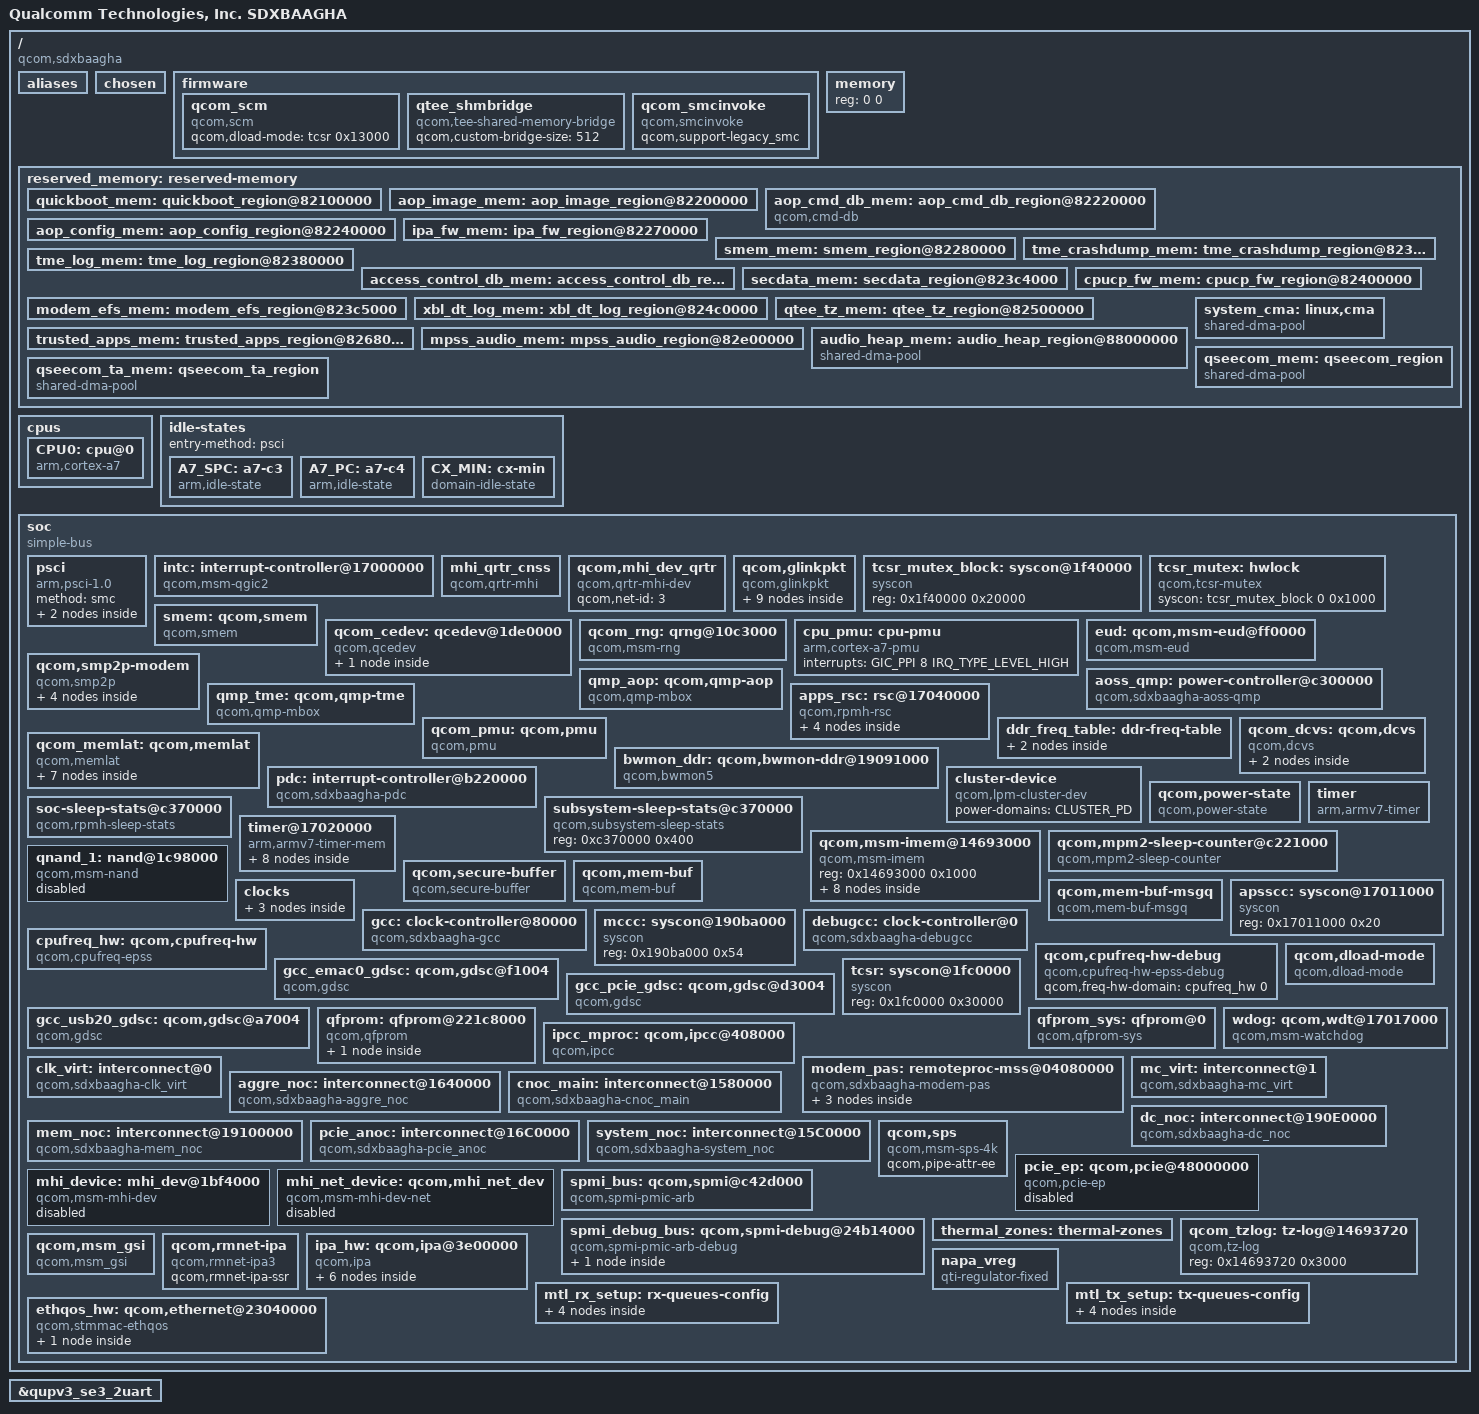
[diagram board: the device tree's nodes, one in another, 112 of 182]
#include <dt-bindings/interrupt-controller/arm-gic.h>
#include <dt-bindings/clock/qcom,rpmh.h>
#include <dt-bindings/clock/qcom,gcc-sdxbaagha.h>
#include <dt-bindings/soc/qcom,ipcc.h>
#include <dt-bindings/interconnect/qcom,icc.h>
#include <dt-bindings/soc/qcom,power-state.h>
#include <dt-bindings/interconnect/qcom,sdxbaagha.h>
#include <dt-bindings/regulator/qcom,rpmh-regulator-levels.h>
#include <dt-bindings/soc/qcom,rpmh-rsc.h>
#include <dt-bindings/gpio/gpio.h>
#include <dt-bindings/spmi/spmi.h>
#include <dt-bindings/soc/qcom,ipcc.h>

/ {
	#address-cells = <1>;
	#size-cells = <1>;

	model = "Qualcomm Technologies, Inc. SDXBAAGHA";
	compatible = "qcom,sdxbaagha";
	qcom,msm-id = <570 0x10000>, <571 0x10000>;
	interrupt-parent = <&intc>;

	aliases {
		serial0 = &qupv3_se3_2uart;
		serial1 = &qupv3_se0_2uart; /* MDM SAP UART Instance */
		hsuart0 = &qupv3_se1_4uart; /* HST BT HCI UART Instance */
	};

	chosen: chosen { };

	firmware: firmware { };

	memory { device_type = "memory"; reg = <0 0>; };

	reserved_memory: reserved-memory {
		#address-cells = <1>;
		#size-cells = <1>;
		ranges;

		quickboot_mem: quickboot_region@82100000 {
			no-map;
			reg = <0x82100000 0x100000>;
		};

		aop_image_mem: aop_image_region@82200000 {
			no-map;
			reg = <0x82200000 0x20000>;
		};

		aop_cmd_db_mem: aop_cmd_db_region@82220000 {
			compatible = "qcom,cmd-db";
			no-map;
			reg = <0x82220000 0x20000>;
		};

		aop_config_mem: aop_config_region@82240000 {
			no-map;
			reg = <0x82240000 0x20000>;
		};

		ipa_fw_mem: ipa_fw_region@82270000 {
			no-map;
			reg = <0x82270000 0x10000>;
		};

		smem_mem: smem_region@82280000 {
			no-map;
			reg = <0x82280000 0xc0000>;
		};

		tme_crashdump_mem: tme_crashdump_region@82340000 {
			no-map;
			reg = <0x82340000 0x40000>;
		};

		tme_log_mem: tme_log_region@82380000 {
			no-map;
			reg = <0x82380000 0x4000>;
		};

		access_control_db_mem: access_control_db_region@82384000 {
			no-map;
			reg = <0x82384000 0x40000>;
		};

		secdata_mem: secdata_region@823c4000 {
			no-map;
			reg = <0x823c4000 0x1000>;
		};

		modem_efs_mem: modem_efs_region@823c5000 {
			no-map;
			reg = <0x823c5000 0x10000>;
		};

		cpucp_fw_mem: cpucp_fw_region@82400000 {
			no-map;
			reg = <0x82400000 0x80000>;
		};

		xbl_dt_log_mem: xbl_dt_log_region@824c0000 {
			no-map;
			reg = <0x824c0000 0x20000>;
		};

		qtee_tz_mem: qtee_tz_region@82500000 {
			no-map;
			reg = <0x82500000 0x180000>;
		};

		trusted_apps_mem: trusted_apps_region@82680000 {
			no-map;
			reg = <0x82680000 0x600000>;
		};

		mpss_audio_mem: mpss_audio_region@82e00000 {
			no-map;
			reg = <0x82e00000 0x5000000>;
		};

		audio_heap_mem: audio_heap_region@88000000 {
			compatible = "shared-dma-pool";
			no-map;
			reg = <0x88000000 0x400000>;
		};

		/* global autoconfigured region for contiguous allocations */
		system_cma: linux,cma {
			compatible = "shared-dma-pool";
			alloc-ranges = <0x00000000 0xffffffff>;
			reusable;
			alignment = <0x400000>;
			size = <0x1800000>;
			linux,cma-default;
		};

		qseecom_mem: qseecom_region {
			compatible = "shared-dma-pool";
			alloc-ranges = <0x00000000 0xffffffff>;
			reusable;
			alignment = <0x400000>;
			size = <0x400000>;
		};

		qseecom_ta_mem: qseecom_ta_region {
			compatible = "shared-dma-pool";
			alloc-ranges = <0x00000000 0xffffffff>;
			reusable;
			alignment = <0x400000>;
			size = <0x400000>;
		};
	};

	cpus {
		#size-cells = <0>;
		#address-cells = <1>;

		CPU0: cpu@0 {
			device_type = "cpu";
			compatible = "arm,cortex-a7";
			reg = <0x0>;
			qcom,freq-domain = <&cpufreq_hw 0>;
			enable-method = "psci";
			cpu-idle-states = <&A7_SPC &A7_PC>;
			power-domains = <&CPU_PD0>;
			power-domain-names = "psci";
			#cooling-cells = <2>;
		};
	};

	idle-states {
		entry-method = "psci";

		A7_SPC: a7-c3 { /* C3 */
			compatible = "arm,idle-state";
			idle-state-name = "standalone-pc";
			entry-latency-us = <350>;
			exit-latency-us = <450>;
			min-residency-us = <1774>;
			arm,psci-suspend-param = <0x40000003>;
			local-timer-stop;
		};

		A7_PC: a7-c4 { /* C4 */
			compatible = "arm,idle-state";
			idle-state-name = "pc";
			entry-latency-us = <550>;
			exit-latency-us = <750>;
			min-residency-us = <6700>;
			arm,psci-suspend-param = <0x40000004>;
			local-timer-stop;
		};

		CX_MIN: cx-min { /* C8 */
			compatible = "domain-idle-state";
			idle-state-name = "cx-min";
			entry-latency-us = <750>;
			exit-latency-us = <2350>;
			min-residency-us = <9144>;
			arm,psci-suspend-param = <0x40000008>;
		};

	};

	soc: soc { };
};

&chosen {
	bootargs = "pcie_ports=compat cpufreq.default_governor=performance";
};

&soc {
	#address-cells = <1>;
	#size-cells = <1>;
	ranges;
	compatible = "simple-bus";

	psci {
		compatible = "arm,psci-1.0";
		 method = "smc";

		CPU_PD0: cpu-pd0 {
			#power-domain-cells = <0>;
			power-domains = <&CLUSTER_PD>;
		};

		CLUSTER_PD: cluster-pd {
			#power-domain-cells = <0>;
			domain-idle-states = <&CX_MIN>;
		};
	};

	intc: interrupt-controller@17000000 {
		compatible = "qcom,msm-qgic2";
		interrupt-controller;
		#interrupt-cells = <3>;
		reg = <0x17000000 0x1000>,
		      <0x17002000 0x1000>;
	};

	mhi_qrtr_cnss {
		compatible = "qcom,qrtr-mhi";
		qcom,dev-id = <0x1103>;
		qcom,net-id = <0>;
		qcom,low-latency;
	};

	qcom,mhi_dev_qrtr {
		compatible = "qcom,qrtr-mhi-dev";
		qcom,net-id = <3>;
	};

	qcom,glinkpkt {
		compatible = "qcom,glinkpkt";

		qcom,glinkpkt-at-mdm0 {
			qcom,glinkpkt-edge = "mpss";
			qcom,glinkpkt-ch-name = "DS";
			qcom,glinkpkt-dev-name = "at_mdm0";
		};

		qcom,glinkpkt-data5-cntl {
			qcom,glinkpkt-edge = "mpss";
			qcom,glinkpkt-ch-name = "DATA5_CNTL";
			qcom,glinkpkt-dev-name = "smdcntl0";
		};

		qcom,glinkpkt-data6-cntl {
			qcom,glinkpkt-edge = "mpss";
			qcom,glinkpkt-ch-name = "DATA6_CNTL";
			qcom,glinkpkt-dev-name = "smdcntl1";
		};

		qcom,glinkpkt-data40-cntl {
			qcom,glinkpkt-edge = "mpss";
			qcom,glinkpkt-ch-name = "DATA40_CNTL";
			qcom,glinkpkt-dev-name = "smdcntl8";
		};

		qcom,glinkpkt-data1 {
			qcom,glinkpkt-edge = "mpss";
			qcom,glinkpkt-ch-name = "DATA1";
			qcom,glinkpkt-dev-name = "smd7";
		};

		qcom,glinkpkt-data4 {
			qcom,glinkpkt-edge = "mpss";
			qcom,glinkpkt-ch-name = "DATA4";
			qcom,glinkpkt-dev-name = "smd8";
		};

		qcom,glinkpkt-data11 {
			qcom,glinkpkt-edge = "mpss";
			qcom,glinkpkt-ch-name = "DATA11";
			qcom,glinkpkt-dev-name = "smd11";
		};

		qcom,glinkpkt-data21 {
			qcom,glinkpkt-edge = "mpss";
			qcom,glinkpkt-ch-name = "DATA21";
			qcom,glinkpkt-dev-name = "smd21";
		};

		qcom,glinkpkt-data22 {
			qcom,glinkpkt-edge = "mpss";
			qcom,glinkpkt-ch-name = "DATA22";
			qcom,glinkpkt-dev-name = "smd22";
		};
	};

	tcsr_mutex_block: syscon@1f40000 {
		compatible = "syscon";
		reg = <0x1f40000 0x20000>;
	};

	tcsr_mutex: hwlock {
		compatible = "qcom,tcsr-mutex";
		syscon = <&tcsr_mutex_block 0 0x1000>;
		#hwlock-cells = <1>;
	};

	smem: qcom,smem {
		compatible = "qcom,smem";
		memory-region = <&smem_mem>;
		hwlocks = <&tcsr_mutex 3>;
	};

	qcom_cedev: qcedev@1de0000 {
		compatible = "qcom,qcedev";
		reg = <0x1de0000 0x20000>,
			<0x1dc4000 0x20000>;
		reg-names = "crypto-base","crypto-bam-base";
		interrupts = <GIC_SPI 252 IRQ_TYPE_LEVEL_HIGH>;
		qcom,bam-pipe-pair = <3>;
		qcom,ce-hw-instance = <0>;
		qcom,ce-device = <0>;
		qcom,ce-hw-shared;
		qcom,bam-ee = <0>;
		qcom,smmu-s1-enable;
		qcom,no-clock-support;
		interconnect-names = "data_path";
		interconnects = <&aggre_noc MASTER_CRYPTO &mc_virt SLAVE_EBI1>;
		iommus = <&apps_smmu 0x00A0 0x0>,
			<&apps_smmu 0x00A1 0x0>;
		qcom,iommu-dma = "atomic";

		qcom_cedev_ns_cb {
			compatible = "qcom,qcedev,context-bank";
			label = "ns_context";
			iommus = <&apps_smmu 0x00A1 0x0>;
		};
	};

	qcom_rng: qrng@10c3000 {
		compatible = "qcom,msm-rng";
		reg = <0x10c3000 0x1000>;
		qcom,no-qrng-config;
		qcom,no-clock-support;
	};

	cpu_pmu: cpu-pmu {
		compatible = "arm,cortex-a7-pmu";
		interrupts = <GIC_PPI 8 IRQ_TYPE_LEVEL_HIGH>;
	};

	eud: qcom,msm-eud@ff0000 {
		compatible = "qcom,msm-eud";
		interrupt-names = "eud_irq";
		interrupt-parent = <&pdc>;
		interrupts = <6 IRQ_TYPE_LEVEL_HIGH>;
		reg = <0xff0000 0x2000>,
			<0xff2000 0x1000>;
		reg-names = "eud_base", "eud_mode_mgr2";
		qcom,secure-eud-en;
		status = "ok";
	};

	qcom,smp2p-modem {
		compatible = "qcom,smp2p";
		qcom,smem = <435>, <428>;
		interrupt-parent = <&ipcc_mproc>;
		interrupts = <IPCC_CLIENT_MPSS IPCC_MPROC_SIGNAL_SMP2P
				IRQ_TYPE_EDGE_RISING>;
		mboxes = <&ipcc_mproc IPCC_CLIENT_MPSS IPCC_MPROC_SIGNAL_SMP2P>;
		qcom,local-pid = <0>;
		qcom,remote-pid = <1>;

		modem_smp2p_out: master-kernel {
			qcom,entry-name = "master-kernel";
			#qcom,smem-state-cells = <1>;
		};

		modem_smp2p_in: slave-kernel {
			qcom,entry-name = "slave-kernel";
			interrupt-controller;
			#interrupt-cells = <2>;
		};

		smp2p_ipa_1_out: qcom,smp2p-ipa-1-out {
			qcom,entry-name = "ipa";
			#qcom,smem-state-cells = <1>;
		};

		 /* ipa - inbound entry from mss */
		smp2p_ipa_1_in: qcom,smp2p-ipa-1-in {
			qcom,entry-name = "ipa";
			interrupt-controller;
			#interrupt-cells = <2>;
		};
	};

	aoss_qmp: power-controller@c300000 {
		compatible = "qcom,sdxbaagha-aoss-qmp";
		reg = <0xc310000 0x1000>;
		interrupt-parent = <&ipcc_mproc>;
		interrupts = <IPCC_CLIENT_AOP
				IPCC_MPROC_SIGNAL_GLINK_QMP
				IRQ_TYPE_EDGE_RISING>;
		mboxes = <&ipcc_mproc IPCC_CLIENT_AOP
				IPCC_MPROC_SIGNAL_GLINK_QMP>;

		#power-domain-cells = <1>;
		#clock-cells = <0>;
	};

	qmp_aop: qcom,qmp-aop {
		compatible = "qcom,qmp-mbox";
		qcom,qmp = <&aoss_qmp>;
		label = "aop";
		#mbox-cells = <1>;
	};

	qmp_tme: qcom,qmp-tme {
		compatible = "qcom,qmp-mbox";
		qcom,remote-pid = <14>;
		mboxes = <&ipcc_mproc IPCC_CLIENT_TME
			  IPCC_MPROC_SIGNAL_GLINK_QMP>;
		mbox-names = "tme_qmp";
		interrupt-parent = <&ipcc_mproc>;
		interrupts = <IPCC_CLIENT_TME
			      IPCC_MPROC_SIGNAL_GLINK_QMP
			      IRQ_TYPE_EDGE_RISING>;

		label = "tme";
		qcom,early-boot;
		priority = <0>;
		mbox-desc-offset = <0x0>;
		#mbox-cells = <1>;
	};

	apps_rsc: rsc@17040000 {
		label = "apps_rsc";
		compatible = "qcom,rpmh-rsc";
		reg = <0x17040000 0x10000>,
		      <0x17050000 0x10000>,
		      <0x17060000 0x10000>;
		reg-names = "drv-0", "drv-1", "drv-2";
		qcom,drv-count = <3>;
		interrupts = <GIC_SPI 16 IRQ_TYPE_LEVEL_HIGH>,
			     <GIC_SPI 17 IRQ_TYPE_LEVEL_HIGH>, /* dummy */
			     <GIC_SPI 17 IRQ_TYPE_LEVEL_HIGH>;
		power-domains = <&CLUSTER_PD>;

		apps_rsc_drv2: drv@2 {
			qcom,drv-id = <2>;
			qcom,tcs-offset = <0xd00>;
			channel@0 {
				qcom,tcs-config = <ACTIVE_TCS    2>,
						  <SLEEP_TCS     3>,
						  <WAKE_TCS      3>,
						  <CONTROL_TCS   0>,
						  <FAST_PATH_TCS 0>;
			};

			apps_bcm_voter: bcm_voter {
				compatible = "qcom,bcm-voter";
			};

			rpmhcc: clock-controller {
				compatible = "qcom,sdxbaagha-rpmh-clk";
				#clock-cells = <1>;
			};
		};
	};

	qcom_pmu: qcom,pmu {
		compatible = "qcom,pmu";
		qcom,pmu-events-tbl =
			< 0x0008 0x01 0xFF 0xFF >,
			< 0x0011 0x01 0xFF 0xFF >,
			< 0x0017 0x01 0xFF 0xFF >;
	};

	ddr_freq_table: ddr-freq-table {
		ddr2 {
			qcom,ddr-type = <2>;
			qcom,freq-tbl =
				<  211200 >,
				<  451200 >,
				<  499200 >,
				<  531500 >;
		};

		ddr4 {
			qcom,ddr-type = <7>;
			qcom,freq-tbl =
				<  211200 >,
				<  451200 >,
				<  556800 >,
				<  681600 >,
				<  768000 >;
		};
	};

	qcom_dcvs: qcom,dcvs {
		compatible = "qcom,dcvs";
		#address-cells = <1>;
		#size-cells = <1>;
		ranges;

		qcom_ddr_dcvs_hw: ddr {
			compatible = "qcom,dcvs-hw";
			qcom,dcvs-hw-type = <0>;
			qcom,bus-width = <4>;
			qcom,freq-tbl = <&ddr_freq_table>;

			ddr_dcvs_sp: sp {
				compatible = "qcom,dcvs-path";
				qcom,dcvs-path-type = <0>;
				interconnects = <&mc_virt MASTER_LLCC
						&mc_virt SLAVE_EBI1>;
			};
		};
	};

	qcom_memlat: qcom,memlat {
		compatible = "qcom,memlat";
		ddr {
			compatible = "qcom,memlat-grp";
			qcom,target-dev = <&qcom_ddr_dcvs_hw>;
			qcom,sampling-path = <&ddr_dcvs_sp>;
			qcom,miss-ev = <0x17>;

			silver {
				compatible = "qcom,memlat-mon";
				qcom,cpulist = <&CPU0>;
				qcom,sampling-enabled;
				ddr2-tbl {
					qcom,ddr-type = <2>;
					qcom,cpufreq-memfreq-tbl =
						<  288000  211200 >,
						<  672000  451200 >,
						< 1248000  499200 >,
						< 1708800  531500 >;
				};

				ddr4-tbl {
					qcom,ddr-type = <7>;
					qcom,cpufreq-memfreq-tbl =
						<  288000  211200 >,
						<  364800  451200 >,
						<  672000  556800 >,
						< 1248000  681600 >,
						< 1708800  768000 >;
				};
			};

			silver-compute {
				compatible = "qcom,memlat-mon";
				qcom,cpulist = <&CPU0>;
				qcom,sampling-enabled;
				qcom,compute-mon;
				ddr2-tbl {
					qcom,ddr-type = <2>;
					qcom,cpufreq-memfreq-tbl =
						< 1248000  211200 >,
						< 1708800  531500 >;
				};

				ddr4-tbl {
					qcom,ddr-type = <7>;
					qcom,cpufreq-memfreq-tbl =
						< 1248000  211200 >,
						< 1708800  768000 >;
				};
			};
		};
	};

	bwmon_ddr: qcom,bwmon-ddr@19091000 {
		compatible = "qcom,bwmon5";
		reg = <0x19091000 0x1000>;
		reg-names = "base";
		interrupts = <GIC_SPI 257 IRQ_TYPE_LEVEL_HIGH>;
		qcom,hw-timer-hz = <19200000>;
		qcom,count-unit = <0x10000>;
		qcom,target-dev = <&qcom_ddr_dcvs_hw>;
	};

	pdc: interrupt-controller@b220000 {
		compatible = "qcom,sdxbaagha-pdc", "qcom,pdc";
		reg = <0xb220000 0x10000>;
		qcom,pdc-ranges = <1 148 6>, <9 156 2>, <17 164 7>,
				  <26 173 1>, <29 176 1>, <40 187 1>,
				  <46 193 6>, <52 266 32>, <84 249 1>,
				  <85 256 1>, <86 315 4>, <90 43 1>,
				  <91 45 1>, <92 154 2>, <94 158 6>,
				  <100 171 2>, <102 174 1>, <103 23 7>,
				  <110 147 1>, <111 31 4>, <115 175 1>,
				  <116 177 10>, <126 188 5>;
		#interrupt-cells = <2>;
		interrupt-parent = <&intc>;
		interrupt-controller;
	};

	cluster-device {
		compatible = "qcom,lpm-cluster-dev";
		power-domains = <&CLUSTER_PD>;
	};

	qcom,power-state {
		compatible = "qcom,power-state";
		qcom,subsys-name = "mpss";
		qcom,rproc-handle = <&modem_pas>;
		qcom,rproc-state = <RPROC_SUSPEND>;
	};

	soc-sleep-stats@c370000 {
		compatible = "qcom,rpmh-sleep-stats";
		reg = <0xc370000 0x400>;
		ss-name = "modem", "apss";
	};

	subsystem-sleep-stats@c370000 {
		compatible = "qcom,subsystem-sleep-stats";
		reg = <0xc370000 0x400>;
	};

	timer {
		compatible = "arm,armv7-timer";
		interrupts = <1 13 0xf08>,
			<1 12 0xf08>,
			<1 10 0xf08>,
			<1 11 0xf08>;
		clock-frequency = <19200000>;
	};

	timer@17020000 {
		#address-cells = <1>;
		#size-cells = <1>;
		ranges;
		compatible = "arm,armv7-timer-mem";
		reg = <0x17020000 0x1000>;
		clock-frequency = <19200000>;

		frame@17021000 {
			frame-number = <0>;
			interrupts = <0 7 0x4>,
				     <0 6 0x4>;
			reg = <0x17021000 0x1000>,
			      <0x17022000 0x1000>;
		};

		frame@17023000 {
			frame-number = <1>;
			interrupts = <0 8 0x4>;
			reg = <0x17023000 0x1000>;
			status = "disabled";
		};

		frame@17024000 {
			frame-number = <2>;
			interrupts = <0 9 0x4>;
			reg = <0x17024000 0x1000>;
			status = "disabled";
		};

		frame@17025000 {
			frame-number = <3>;
			interrupts = <0 10 0x4>;
			reg = <0x17025000 0x1000>;
			status = "disabled";
		};

		frame@17026000 {
			frame-number = <4>;
			interrupts = <0 11 0x4>;
			reg = <0x17026000 0x1000>;
			status = "disabled";
		};

		frame@17027000 {
			frame-number = <5>;
			interrupts = <0 12 0x4>;
			reg = <0x17027000 0x1000>;
			status = "disabled";
		};

		frame@17028000 {
			frame-number = <6>;
			interrupts = <0 13 0x4>;
			reg = <0x17028000 0x1000>;
			status = "disabled";
		};

		frame@17029000 {
			frame-number = <7>;
			interrupts = <0 14 0x4>;
			reg = <0x17029000 0x1000>;
			status = "disabled";
		};
	};

	qcom,msm-imem@14693000 {
		compatible = "qcom,msm-imem";
		reg = <0x14693000 0x1000>;
		ranges = <0x0 0x14693000 0x1000>;
		#address-cells = <1>;
		#size-cells = <1>;

		mem_dump_table@10  {
			compatible = "qcom,msm-imem-mem_dump_table";
			reg = <0x10 0x8>;
		};

		restart_reason@65c {
			compatible = "qcom,msm-imem-restart_reason";
			reg = <0x65c 0x4>;
		};

		dload_type@1c {
			compatible = "qcom,msm-imem-dload-type";
			reg = <0x1c 0x4>;
		};

		boot_stats@6b0 {
			compatible = "qcom,msm-imem-boot_stats";
			reg = <0x6b0 0x20>;
		};

		kaslr_offset@6d0 {
			compatible = "qcom,msm-imem-kaslr_offset";
			reg = <0x6d0 0xc>;
		};

		pil@94c {
			compatible = "qcom,pil-reloc-info";
			reg = <0x94c 0xc8>;
		};

		pil@6dc {
			compatible = "qcom,msm-imem-pil-disable-timeout";
			reg = <0x6dc 0x4>;
		};

		diag_dload@c8 {
			compatible = "qcom,msm-imem-diag-dload";
			reg = <0xc8 0xc8>;
		};
	};

	qcom,mpm2-sleep-counter@c221000 {
		compatible = "qcom,mpm2-sleep-counter";
		reg = <0xc221000 0x1000>;
		clock-frequency = <32768>;
	};

	qnand_1: nand@1c98000 {
		compatible = "qcom,msm-nand";
		reg =   <0x01c98000 0x1000>,
			<0x01c9c000 0x1c000>;
		reg-names =     "nand_phys",
				"bam_phys";
		qcom,reg-adjustment-offset = <0x4000>;

		interrupts = <GIC_SPI 135 IRQ_TYPE_LEVEL_HIGH>;
		interrupt-names = "bam_irq";

		clock-names = "core_clk";
		clocks = <&rpmhcc RPMH_QPIC_CLK>;

		interconnects = <&aggre_noc MASTER_QPIC &mc_virt SLAVE_EBI1>;
		interconnect-names = "nand-ddr";
		qcom,msm-bus,name = "qpic_nand";
		qcom,msm-bus,num-cases = <2>;
		qcom,msm-bus,num-paths = <1>;
		qcom,msm-bus,vectors-KBps =
			<0 0>,
		/* Voting for max b/w on PNOC bus for now */
			<1057800 725760>;

		iommus = <&apps_smmu 0x160 0x3>;
		qcom,iommu-dma = "atomic";

		status = "disabled";
	};

	qcom,secure-buffer {
		compatible = "qcom,secure-buffer";
	};

	qcom,mem-buf {
		compatible = "qcom,mem-buf";
		qcom,mem-buf-capabilities = "supplier";
		qcom,vmid = <3>;
	};

	qcom,mem-buf-msgq {
		compatible = "qcom,mem-buf-msgq";
	};

	clocks {
		xo_board: xo_board {
			compatible = "fixed-clock";
			clock-frequency = <38400000>;
			clock-output-names = "xo_board";
			#clock-cells = <0>;
		};

		sleep_clk: sleep_clk {
			compatible = "fixed-clock";
			clock-frequency = <32000>;
			clock-output-names = "sleep_clk";
			#clock-cells = <0>;
		};

		pcie_pipe_clk: pcie_pipe_clk {
			compatible = "fixed-clock";
			clock-frequency = <1000>;
			clock-output-names = "pcie_pipe_clk";
			#clock-cells = <0>;
		};
	};

	gcc: clock-controller@80000 {
		compatible = "qcom,sdxbaagha-gcc", "syscon";
		reg = <0x80000 0x1f4200>;
		reg-name = "cc_base";
		vdd_cx-supply = <&VDD_CX_LEVEL>;
		vdd_mxa-supply = <&VDD_MXA_LEVEL>;
		vdd_mxc-supply = <&VDD_MXC_LEVEL>;
		clocks = <&rpmhcc RPMH_CXO_CLK>,
			 <&pcie_pipe_clk>,
			 <&sleep_clk>;
		clock-names = "bi_tcxo",
			      "pcie_pipe_clk",
			      "sleep_clk";
		#clock-cells = <1>;
		#reset-cells = <1>;
	};

	apsscc: syscon@17011000 {
		compatible = "syscon";
		reg = <0x17011000 0x20>;
	};

	mccc: syscon@190ba000 {
		compatible = "syscon";
		reg = <0x190ba000 0x54>;
	};

	debugcc: clock-controller@0 {
		compatible = "qcom,sdxbaagha-debugcc";
		qcom,gcc = <&gcc>;
		qcom,mccc = <&mccc>;
		qcom,apsscc = <&apsscc>;
		clocks = <&rpmhcc RPMH_CXO_CLK>,
			 <&gcc 0>;
		clock-names = "xo_clk_src",
			      "gcc";
		#clock-cells = <1>;
	};

	cpufreq_hw: qcom,cpufreq-hw {
		compatible = "qcom,cpufreq-epss";
		reg = <0x17191000 0x1000>;
		reg-names = "freq-domain0";
		clocks = <&rpmhcc RPMH_CXO_CLK>, <&gcc GPLL0>;
		clock-names = "xo", "alternate";
		interrupts = <GIC_SPI 30 IRQ_TYPE_LEVEL_HIGH>;
		interrupt-names = "dcvsh0_int";
		#freq-domain-cells = <1>;
	};

	qcom,cpufreq-hw-debug {
		compatible = "qcom,cpufreq-hw-epss-debug";
		qcom,freq-hw-domain = <&cpufreq_hw 0>;
	};

	/* GCC GDSCs */
	gcc_emac0_gdsc: qcom,gdsc@f1004 {
		compatible = "qcom,gdsc";
		reg = <0xf1004 0x4>;
		regulator-name = "gcc_emac0_gdsc";
		parent-supply = <&VDD_MXC_LEVEL>;
		qcom,retain-regs;
		qcom,support-hw-trigger;
	};

	gcc_pcie_gdsc: qcom,gdsc@d3004 {
		compatible = "qcom,gdsc";
		reg = <0xd3004 0x4>;
		regulator-name = "gcc_pcie_gdsc";
		parent-supply = <&VDD_CX_LEVEL>;
		qcom,retain-regs;
		qcom,support-hw-trigger;
	};

	gcc_usb20_gdsc: qcom,gdsc@a7004 {
		compatible = "qcom,gdsc";
		reg = <0xa7004 0x4>;
		regulator-name = "gcc_usb20_gdsc";
		parent-supply = <&VDD_CX_LEVEL>;
		qcom,retain-regs;
	};

	tcsr: syscon@1fc0000 {
		compatible = "syscon";
		reg = <0x1fc0000 0x30000>;
	};

	qcom,dload-mode {
		compatible = "qcom,dload-mode";
	};

	qfprom: qfprom@221c8000 {
		compatible = "qcom,qfprom";
		reg = <0x221c8000 0x1000>;
		#address-cells = <1>;
		#size-cells = <1>;
		read-only;
		ranges;

		boot_config: boot_config@600 {
			reg = <0x600 0x1>;
		};
	};

	qfprom_sys: qfprom@0 {
		compatible = "qcom,qfprom-sys";
		nvmem-cells = <&boot_config>;
		nvmem-cell-names = "boot_config";
	};

	wdog: qcom,wdt@17017000 {
		compatible ="qcom,msm-watchdog";
		reg = <0x17017000 0x1000>;
		reg-names = "wdt-base";
		interrupts = <GIC_PPI 3 IRQ_TYPE_LEVEL_HIGH>;
	};

	ipcc_mproc: qcom,ipcc@408000 {
		compatible = "qcom,ipcc";
		reg = <0x408000 0x1000>;
		interrupts = <GIC_SPI 241 IRQ_TYPE_LEVEL_HIGH>;
		interrupt-controller;
		#interrupt-cells = <3>;
		#mbox-cells = <2>;
	};

	modem_pas: remoteproc-mss@04080000 {
		compatible = "qcom,sdxbaagha-modem-pas";
		reg = <0x4080000 0x10000>;
		status = "ok";

		clocks = <&rpmhcc RPMH_CXO_CLK>;
		clock-names = "xo";

		cx-supply = <&VDD_CX_LEVEL>;
		cx-uV-uA = <RPMH_REGULATOR_LEVEL_TURBO 100000>;
		mx-supply = <&VDD_MODEM_LEVEL>;
		mx-uV-uA = <RPMH_REGULATOR_LEVEL_NOM_L1 100000>;
		reg-names = "cx", "mx";

		qcom,signal-aop;
		qcom,qmp = <&aoss_qmp>;
		memory-region = <&mpss_audio_mem>;

		/* Inputs from mss */
		interrupts-extended = <&intc GIC_SPI 250 IRQ_TYPE_EDGE_RISING>,
					<&modem_smp2p_in 0 0>,
					<&modem_smp2p_in 2 0>,
					<&modem_smp2p_in 1 0>,
					<&modem_smp2p_in 3 0>,
					<&modem_smp2p_in 7 0>,
					<&modem_smp2p_in 9 0>;

		interrupt-names = "wdog",
				"fatal",
				"handover",
				"ready",
				"stop-ack",
				"shutdown-ack",
				"deepsleep-ack";
		/* Outputs to mss */
		qcom,smem-states = <&modem_smp2p_out 0>;
		qcom,smem-state-names = "stop";

		glink_edge: glink-edge {
			qcom,remote-pid = <1>;
			transport = "smem";
			mboxes = <&ipcc_mproc IPCC_CLIENT_MPSS 3>;
			mbox-names = "mpss_smem";
			interrupt-parent = <&ipcc_mproc>;
			interrupts = <IPCC_CLIENT_MPSS 3 IRQ_TYPE_EDGE_RISING>;

			label = "modem";
			qcom,glink-label = "mpss";

			qcom,modem_qrtr {
				qcom,glink-channels = "IPCRTR";
				qcom,low-latency;
				qcom,intents = <0x800  5
						0x2000 3
						0x4400 2>;
			};

			qcom,modem_ds {
				qcom,glink-channels = "DS";
				qcom,intents = <0x4000 0x2>;
			};
		};
	};

	clk_virt: interconnect@0 {
		compatible = "qcom,sdxbaagha-clk_virt";
		#interconnect-cells = <1>;
		qcom,bcm-voter-names = "hlos";
		qcom,bcm-voters = <&apps_bcm_voter>;
	};

	mc_virt: interconnect@1 {
		compatible = "qcom,sdxbaagha-mc_virt";
		#interconnect-cells = <1>;
		qcom,bcm-voter-names = "hlos";
		qcom,bcm-voters = <&apps_bcm_voter>;
	};

	aggre_noc: interconnect@1640000 {
		reg = <0x1640000 0x33400>;
		compatible = "qcom,sdxbaagha-aggre_noc";
		#interconnect-cells = <1>;
		qcom,bcm-voter-names = "hlos";
		qcom,bcm-voters = <&apps_bcm_voter>;
	};

	cnoc_main: interconnect@1580000 {
		reg = <0x01580000 0x19200>;
		compatible = "qcom,sdxbaagha-cnoc_main";
		#interconnect-cells = <1>;
		qcom,bcm-voter-names = "hlos";
		qcom,bcm-voters = <&apps_bcm_voter>;
	};

	dc_noc: interconnect@190E0000 {
		reg = <0x190E0000 0x5080>;
		compatible = "qcom,sdxbaagha-dc_noc";
		#interconnect-cells = <1>;
		qcom,bcm-voter-names = "hlos";
		qcom,bcm-voters = <&apps_bcm_voter>;
	};

	mem_noc: interconnect@19100000 {
		reg = <0x19100000 0x2D080>;
		compatible = "qcom,sdxbaagha-mem_noc";
		#interconnect-cells = <1>;
		qcom,bcm-voter-names = "hlos";
		qcom,bcm-voters = <&apps_bcm_voter>;
	};

	pcie_anoc: interconnect@16C0000 {
		reg = <0x16C0000 0x16400>;
		compatible = "qcom,sdxbaagha-pcie_anoc";
		#interconnect-cells = <1>;
		qcom,bcm-voter-names = "hlos";
		qcom,bcm-voters = <&apps_bcm_voter>;
	};

	system_noc: interconnect@15C0000 {
		reg = <0x15C0000 0x14080>;
		compatible = "qcom,sdxbaagha-system_noc";
		#interconnect-cells = <1>;
		qcom,bcm-voter-names = "hlos";
		qcom,bcm-voters = <&apps_bcm_voter>;
	};

	qcom,sps {
		compatible = "qcom,msm-sps-4k";
		qcom,pipe-attr-ee;
	};

	pcie_ep: qcom,pcie@48000000 {
		compatible = "qcom,pcie-ep";

		reg = <0x48002000 0x1000>,
		      <0x48000000 0xf1d>,
		      <0x48000f20 0xa8>,
		      <0x48001000 0x1000>,
		      <0x01bf0000 0x4000>,
		      <0x01bf6000 0x2000>,
		      <0x01bf4000 0x1000>,
		      <0x01fcb000 0x1000>,
		      <0xc2fa000 0x4>;
		reg-names = "msi", "dm_core", "elbi", "iatu", "parf", "phy",
				"mmio", "tcsr_pcie_perst_en", "aoss_cc_reset";

		#address-cells = <0>;
		interrupt-parent = <&pcie_ep>;
		interrupts = <0>;
		#interrupt-cells = <1>;
		interrupt-map-mask = <0xffffffff>;
		interrupt-map = <0 &intc GIC_SPI 225 IRQ_TYPE_LEVEL_HIGH>;
		interrupt-names = "int_global";

		pinctrl-names = "default";
		pinctrl-0 = <&pcie_ep_clkreq_default &pcie_ep_perst_default
			&pcie_ep_wake_default>;

		clkreq-gpio = <&tlmm 56 GPIO_ACTIVE_HIGH>;
		perst-gpio = <&tlmm 57 GPIO_ACTIVE_HIGH>;
		wake-gpio = <&tlmm 53 GPIO_ACTIVE_HIGH>;

		gdsc-vdd-supply = <&gcc_pcie_gdsc>;
		vreg-1p2-supply = <&L14A>;
		vreg-0p9-supply = <&L3A>;
		vreg-mx-supply = <&VDD_MXA_LEVEL>;

		qcom,vreg-1p2-voltage-level = <1200000 1200000 15000>;
		qcom,vreg-0p9-voltage-level = <912000 880000 48100>;
		qcom,vreg-mx-voltage-level = <RPMH_REGULATOR_LEVEL_MAX
					      RPMH_REGULATOR_LEVEL_NOM 0>;

		clocks = <&gcc GCC_PCIE_PIPE_CLK>,
			<&gcc GCC_PCIE_CFG_AHB_CLK>,
			<&gcc GCC_PCIE_MSTR_AXI_CLK>,
			<&gcc GCC_PCIE_SLV_AXI_CLK>,
			<&gcc GCC_PCIE_AUX_CLK>,
			<&gcc GCC_PCIE_0_CLKREF_EN>,
			<&gcc GCC_PCIE_SLEEP_CLK>,
			<&gcc GCC_PCIE_SLV_Q2A_AXI_CLK>,
			<&gcc GCC_PCIE_PIPE_CLK_SRC>,
			<&pcie_pipe_clk>,
			<&rpmhcc RPMH_CXO_CLK>;

		clock-names = "pcie_pipe_clk", "pcie_cfg_ahb_clk",
				"pcie_mstr_axi_clk", "pcie_slv_axi_clk",
				"pcie_aux_clk", "pcie_ldo",
				"pcie_sleep_clk", "pcie_slv_q2a_axi_clk",
				"pcie_pipe_clk_mux", "pcie_pipe_clk_ext_src",
				"pcie_0_ref_clk_src";

		resets = <&gcc GCC_PCIE_BCR>, <&gcc GCC_PCIE_PHY_BCR>;
		reset-names = "pcie_core_reset", "pcie_phy_reset";

		interconnect-names = "icc_path";
		interconnects = <&pcie_anoc MASTER_PCIE_0 &mc_virt SLAVE_EBI1>;

		qcom,pcie-vendor-id = /bits/ 16 <0x17cb>;
		qcom,pcie-device-id = /bits/ 16 <0x011a>;
		qcom,pcie-link-speed = <1>;
		qcom,pcie-phy-ver = <8>;
		qcom,pcie-active-config;
		qcom,pcie-aggregated-irq;
		qcom,pcie-mhi-a7-irq;
		qcom,phy-status-reg = <0x214>;
		qcom,mhi-soc-reset-offset = <0xb001b8>;
		qcom,pcie-cesta-clkreq-offset = <0x30b8>;
		qcom,aoss-rst-clr;
		qcom,aux-clk = <0x13>;
		nvmem-cells = <&boot_config>;
		nvmem-cell-names = "boot_conf";
		qcom,fast-boot-mask = <0x1e>;
		qcom,host-bypass-mask = <0x40>;
		qcom,fast-boot-values = <0x3>;
		qcom,phy-init = <0x0240 0x01 0x0
				0x0094 0x00 0x0
				0x0154 0x31 0x0
				0x016c 0x08 0x0
				0x0058 0x0f 0x0
				0x00a4 0x42 0x0
				0x0110 0x24 0x0
				0x011c 0x03 0x0
				0x0118 0xb4 0x0
				0x010c 0x02 0x0
				0x01bc 0x11 0x0
				0x00bc 0x19 0x0
				0x00b0 0x04 0x0
				0x00ac 0xff 0x0
				0x00c4 0x14 0x0
				0x00b8 0x09 0x0
				0x00b4 0xff 0x0
				0x0158 0x01 0x0
				0x0074 0x20 0x0
				0x007c 0x13 0x0
				0x0084 0x00 0x0
				0x0078 0x12 0x0
				0x0080 0x12 0x0
				0x0088 0x00 0x0
				0x01b0 0x1d 0x0
				0x01ac 0x56 0x0
				0x01b8 0x17 0x0
				0x01b4 0x78 0x0
				0x004c 0x07 0x0
				0x0050 0x07 0x0
				0x00f0 0x01 0x0
				0x00ec 0xfb 0x0
				0x00f8 0x01 0x0
				0x00f4 0xfb 0x0
				0x000c 0x02 0x0
				0x01a0 0x14 0x0
				0x0ee4 0x20 0x0
				0x0e84 0x75 0x0
				0x0e90 0x3f 0x0
				0x115c 0x7f 0x0
				0x1160 0xff 0x0
				0x1164 0xbf 0x0
				0x1168 0x3f 0x0
				0x116c 0xd8 0x0
				0x1170 0xdc 0x0
				0x1174 0xdc 0x0
				0x1178 0x5c 0x0
				0x117c 0x34 0x0
				0x1180 0xa6 0x0
				0x1190 0x34 0x0
				0x1194 0x38 0x0
				0x10d8 0x0f 0x0
				0x0e3c 0x12 0x0
				0x0e40 0x01 0x0
				0x10dc 0x00 0x0
				0x104c 0x08 0x0
				0x1050 0x08 0x0
				0x1044 0xf0 0x0
				0x11a4 0x38 0x0
				0x10cc 0xf0 0x0
				0x10f4 0x07 0x0
				0x1008 0x09 0x0
				0x1014 0x05 0x0
				0x0654 0x00 0x0
				0x06a8 0x0f 0x0
				0x0388 0x77 0x0
				0x0398 0x0b 0x0
				0x02dc 0x0d 0x0
				0x0200 0x00 0x0
				0x0244 0x03 0x0>;

		status = "disabled";
	};

	mhi_device: mhi_dev@1bf4000 {
		compatible = "qcom,msm-mhi-dev";
		reg = <0x1bf4000 0x1000>;
		reg-names = "mhi_mmio_base";
		qcom,mhi-ep-msi = <0>;
		qcom,mhi-version = <0x1000000>;
		qcom,use-mhi-dma-software-channel;
		interrupts = <GIC_SPI 242 IRQ_TYPE_LEVEL_HIGH>;
		interrupt-names = "mhi-device-inta";
		qcom,mhi-ifc-id = <0x011a17cb>;
		qcom,mhi-interrupt;
		qcom,no-m0-timeout;
		qcom,mhi-has-smmu;
		iommus = <&apps_smmu 0x400 0x0>;
		qcom,iommu-dma = "bypass";
		status = "disabled";
	};

	mhi_net_device: qcom,mhi_net_dev {
		compatible = "qcom,msm-mhi-dev-net";
		status = "disabled";
	};

	spmi_bus: qcom,spmi@c42d000 {
		compatible = "qcom,spmi-pmic-arb";
		reg = <0xc42d000 0x4000>,
		      <0xc400000 0x3000>,
		      <0xc500000 0x400000>,
		      <0xc440000 0x80000>,
		      <0xc4c0000 0x10000>;
		reg-names = "cnfg", "core", "chnls", "obsrvr", "intr";
		interrupts-extended = <&pdc 1 IRQ_TYPE_LEVEL_HIGH>;
		interrupt-names = "periph_irq";
		interrupt-controller;
		#interrupt-cells = <4>;
		#address-cells = <2>;
		#size-cells = <0>;
		cell-index = <0>;
		qcom,channel = <0>;
		qcom,ee = <0>;
		qcom,bus-id = <0>;
	};

	spmi_debug_bus: qcom,spmi-debug@24b14000 {
		compatible = "qcom,spmi-pmic-arb-debug";
		reg = <0x24b14000 0x60>, <0x221c8784 0x4>;
		reg-names = "core", "fuse";
		clocks = <&aoss_qmp>;
		clock-names = "core_clk";
		qcom,fuse-enable-bit = <18>;
		#address-cells = <2>;
		#size-cells = <0>;
		depends-on-supply = <&spmi_bus>;

		qcom,pmx35-debug@0 {
			compatible = "qcom,spmi-pmic";
			reg = <0 SPMI_USID>;
			#address-cells = <2>;
			#size-cells = <0>;
			qcom,can-sleep;
		};
	};

	thermal_zones: thermal-zones {
	};

	qcom_tzlog: tz-log@14693720 {
		compatible = "qcom,tz-log";
		reg = <0x14693720 0x3000>;
	};

	qcom,msm_gsi {
		compatible = "qcom,msm_gsi";
	};

	qcom,rmnet-ipa {
		compatible = "qcom,rmnet-ipa3";
		qcom,rmnet-ipa-ssr;
	};

	ipa_hw: qcom,ipa@3e00000 {
		compatible = "qcom,ipa";
		reg =
			<0x3e00000 0x84000>,
			<0x3e04000 0xfc000>;
		reg-names = "ipa-base", "gsi-base";
		qcom,ipa-cfg-offset = <0x0140000>;
		interrupts =
			<0 314 IRQ_TYPE_LEVEL_HIGH>,
			<0 208 IRQ_TYPE_LEVEL_HIGH>;
		interrupt-names = "ipa-irq", "gsi-irq";
		qcom,ipa-hw-ver = <23>; /* IPA core version = IPAv5.2 */
		qcom,ipa-hw-mode = <0>;
		qcom,platform-type = <0>; /* MDM platform */
		qcom,ee = <0>;
		qcom,entire-ipa-block-size = <0x200000>;
		qcom,use-ipa-tethering-bridge;
		qcom,mhi-event-ring-id-limits = <9 15>; /* start and end */
		qcom,modem-cfg-emb-pipe-flt;
		qcom,use-xbl-boot;
		qcom,ipa-wdi3-over-gsi;
		qcom,wlan-ce-db-over-pcie;
		qcom,wan-rx-ring-size = <96>;
		qcom,lan-rx-ring-size = <96>;
		qcom,arm-smmu;
		qcom,ipa-endp-delay-wa-v2;
		qcom,tx-wrapper-cache-max-size = <400>;
		qcom,ipa-gpi-event-rp-ddr;
		qcom,max_num_smmu_cb = <4>;
		clock-names = "core_clk";
		clocks = <&rpmhcc RPMH_IPA_CLK>;
		qcom,interconnect,num-cases = <5>;
		qcom,interconnect,num-paths = <3>;
		interconnects = <&aggre_noc MASTER_IPA &mem_noc SLAVE_LLCC>,
				<&mc_virt MASTER_LLCC &mc_virt SLAVE_EBI1>,
				<&mem_noc MASTER_APPSS_PROC &cnoc_main SLAVE_IPA_CFG>;
		interconnect-names = "ipa_to_llcc", "llcc_to_ebi1", "appss_to_ipa";
		/* No vote */
		qcom,no-vote =
		<0 0 0 0 0 0>;
		/* SVS2 */
		qcom,svs2 =
		<18000 0 590000 1900000 0 76800>;

		/* SVS */
		qcom,svs =
		<400000 0 1200000 2800000 0 150000>;

		/* NOMINAL */
		qcom,nominal =
		<670000 0 2400000 5500000 0 400000>;

		/* TURBO */
		qcom,turbo =
		<1380000 0 3600000 5500000 0 400000>;

		qcom,bus-vector-names = "MIN", "SVS2", "SVS", "NOMINAL",
			"TURBO";
		qcom,throughput-threshold = <600 2500 5000>;
		qcom,scaling-exceptions = <>;
		/* smp2p information */
		qcom,smp2p_map_ipa_1_out {
			compatible = "qcom,smp2p-map-ipa-1-out";
			qcom,smem-states = <&smp2p_ipa_1_out 0>;
			qcom,smem-state-names = "ipa-smp2p-out";
		};

		qcom,smp2p_map_ipa_1_in {
			compatible = "qcom,smp2p-map-ipa-1-in";
			interrupts-extended = <&smp2p_ipa_1_in 0 0>;
			interrupt-names = "ipa-smp2p-in";
		};

		ipa_smmu_ap: ipa_smmu_ap {
			compatible = "qcom,ipa-smmu-ap-cb";
			iommus = <&apps_smmu 0x000 0x0>;
			qcom,iommu-dma-addr-pool = <0x20000000 0x20000000>;
			qcom,additional-mapping =
				/* modem tables in IMEM */
				<0x14691000 0x14691000 0x2000>;
			qcom,iommu-dma = "atomic";
			qcom,ipa-q6-smem-size = <36864>;
		};

		ipa_smmu_wlan: ipa_smmu_wlan {
			compatible = "qcom,ipa-smmu-wlan-cb";
			iommus = <&apps_smmu 0x001 0x0>;
			qcom,iommu-dma = "atomic";
		};

		ipa_smmu_uc: ipa_smmu_uc {
			compatible = "qcom,ipa-smmu-uc-cb";
			iommus = <&apps_smmu 0x002 0x0>;
			qcom,iommu-dma-addr-pool = <0x20000000 0x20000000>;
			qcom,iommu-dma = "atomic";
		};

		ipa_smmu_11ad: ipa_smmu_11ad {
			compatible = "qcom,ipa-smmu-11ad-cb";
			iommus = <&apps_smmu 0x003 0x0>;
			qcom,shared-cb;
			qcom,iommu-group = <>;
		};
	};

	napa_vreg: napa_vreg {
		compatible = "qti-regulator-fixed";
		regulator-name = "napa_vreg";
		gpio = <&tlmm 108 GPIO_ACTIVE_HIGH>;
		regulator-min-microvolt = <1050000>;
		regulator-max-microvolt = <1050000>;
		enable-active-high;
		regulator-enable-ramp-delay = <80000>;
	};

	mtl_rx_setup: rx-queues-config {
		snps,rx-queues-to-use = <2>;
		snps,rx-sched-sp;

		queue0 {
			snps,dcb-algorithm;
			snps,map-to-dma-channel = <0x0>;
			snps,route-up;
			snps,priority = <0x1>;
		};

		queue1 {
			snps,dcb-algorithm;
			snps,map-to-dma-channel = <0x1>;
			snps,route-ptp;
		};

		queue2 {
			snps,avb-algorithm;
			snps,map-to-dma-channel = <0x2>;
			snps,route-avcp;
		};

		queue3 {
			snps,avb-algorithm;
			snps,map-to-dma-channel = <0x3>;
			snps,priority = <0xC>;
		};
	};

	mtl_tx_setup: tx-queues-config {
		snps,tx-queues-to-use = <2>;
		snps,tx-sched-sp;
		queue0 {
			snps,dcb-algorithm;
		};

		queue1 {
			snps,dcb-algorithm;
		};

		queue2 {
			snps,avb-algorithm;
			snps,send_slope = <0x1000>;
			snps,idle_slope = <0x1000>;
			snps,high_credit = <0x3E800>;
			snps,low_credit = <0xFFC18000>;
		};

		queue3 {
			snps,avb-algorithm;
			snps,send_slope = <0x1000>;
			snps,idle_slope = <0x1000>;
			snps,high_credit = <0x3E800>;
			snps,low_credit = <0xFFC18000>;
		};

	};

	ethqos_hw: qcom,ethernet@23040000 {
		compatible = "qcom,stmmac-ethqos", "snps,dwmac-4.20a";
		qcom,arm-smmu;
		reg = <0x23040000 0x10000>,
				<0x23056000 0x100>,
				<0x00FF6000 0xE10>;

		reg-names = "stmmaceth", "rgmii", "serdes";
		clocks = <&gcc GCC_EMAC0_AXI_CLK>,
				<&gcc GCC_EMAC0_SLV_AHB_CLK>,
				<&gcc GCC_EMAC0_PTP_CLK>,
				<&gcc GCC_EMAC0_PHY_AUX_CLK>,
				<&gcc GCC_EMAC_0_CLKREF_EN>;
		clock-names = "stmmaceth", "pclk", "ptp_ref", "phyaux", "sgmi_ref";
		snps,ptp-ref-clk-rate = <250000000>;
		snps,ptp-req-clk-rate = <96000000>;
		interrupts-extended = <&intc GIC_SPI 261 IRQ_TYPE_LEVEL_HIGH>;

		interrupt-names = "macirq";

		snps,tso;
		snps,pbl = <32>;
		snps,rxpbl = <16>;
		rx-fifo-depth = <8192>;
		tx-fifo-depth = <8192>;

		snps,mtl-rx-config = <&mtl_rx_setup>;
		snps,mtl-tx-config = <&mtl_tx_setup>;

		vreg_emac_phy-supply = <&napa_vreg>;

		gdsc_emac-supply = <&gcc_emac0_gdsc>;

		phy-mode = "sgmii";
		snps,reset-gpio = <&tlmm 97 1>;
		snps,reset-active-low;
		snps,reset-delays-us = <0 11000 70000>;
		pinctrl-names = "dev-emac-mdc",
				"dev-emac-mdio";

		pinctrl-0 = <&emac_mdc>;
		pinctrl-1 = <&emac_mdio>;

		snps,ps-speed = <1000>;
		managed = "auto";
		eth-c22-mdio-probe;
		snps,crc_strip;
		pcs-v3;
		sw-dma-tx-desc-cnt = <128>;
		sw-dma-rx-desc-cnt = <128>;

		interconnect-names = "axi_icc_path", "apb_icc_path";
		interconnects = <&aggre_noc MASTER_EMAC &mc_virt SLAVE_EBI1>,
				<&mem_noc MASTER_APPSS_PROC &cnoc_main SLAVE_EMAC_CFG>;

		ethqos_emb_smmu: ethqos_emb_smmu {
			compatible = "qcom,emac-smmu-embedded";
			iommus = <&apps_smmu 0x100 0xf>;
			qcom,iommu-dma = "fastmap";
			qcom,iommu-dma-addr-pool = <0x80000000 0x0FE40000>;
			qcom,iommu-geometry = <0x80000000 0x0FE40000>;
		};
	};
};

&firmware {
	qcom_scm {
		compatible = "qcom,scm";
		qcom,dload-mode = <&tcsr 0x13000>;
	};

	qtee_shmbridge {
		compatible = "qcom,tee-shared-memory-bridge";
		qcom,custom-bridge-size = <512>;
	};

	qcom_smcinvoke {
		compatible = "qcom,smcinvoke";
		qcom,support-legacy_smc;
	};
};

#include "ipcc-test-sdxbaagha.dtsi"
#include "sdxbaagha-pinctrl.dtsi"
#include "sdxbaagha-debug.dtsi"
#include "sdxbaagha-dma-heaps.dtsi"
#include "msm-arm-smmu-sdxbaagha.dtsi"
#include "sdxbaagha-pcie.dtsi"
#include "sdxbaagha-qupv3.dtsi"
#include "sdxbaagha-usb.dtsi"
#include "sdxbaagha-coresight.dtsi"
#include "sdxbaagha-pmic-overlay.dtsi"
#include "sdxbaagha-regulators.dtsi"

&qupv3_se3_2uart {
	status = "ok";
};

#include "sdxbaagha-thermal.dtsi"
